AUTOSAR XML (schema 314)
package /ComponentType
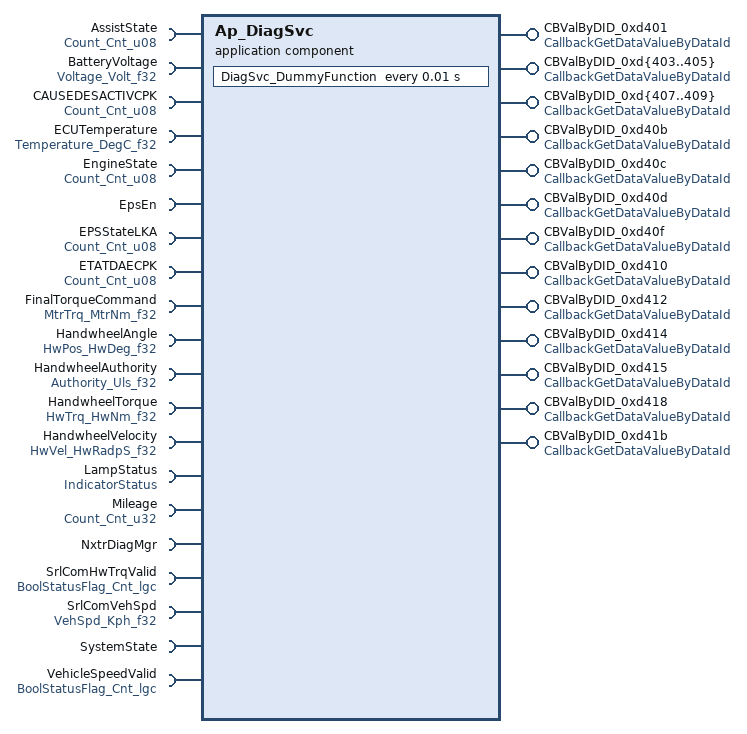
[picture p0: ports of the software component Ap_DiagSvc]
  application software component type Ap_DiagSvc
    17 x provide port, all with server-com-spec{operation=GetDataValueByDataIdentifier, queue-length=1}, provided-interface=CallbackGetDataValueByDataId:
      CBValByDID_0xd401
      CBValByDID_0xd{403..405}
      CBValByDID_0xd{407..409}
      CBValByDID_0xd40b
      CBValByDID_0xd40c
      CBValByDID_0xd40d
      CBValByDID_0xd40f
      CBValByDID_0xd410
      CBValByDID_0xd412
      CBValByDID_0xd414
      CBValByDID_0xd415
      CBValByDID_0xd418
      CBValByDID_0xd41b
    20 x require port:
      AssistState: unqueued-receiver-com-spec{data-element=Cnt_u08, init-value=D_ZERO_CNT_U8}, required-interface=Count_Cnt_u08
      BatteryVoltage: unqueued-receiver-com-spec{data-element=Volt_f32, init-value=D_ZERO_ULS_F32}, required-interface=Voltage_Volt_f32
      CAUSEDESACTIVCPK: unqueued-receiver-com-spec{data-element=Cnt_u08, init-value=D_ZERO_CNT_U8}, required-interface=Count_Cnt_u08
      ECUTemperature: unqueued-receiver-com-spec{data-element=DegC_f32, init-value=D_ZERO_ULS_F32}, required-interface=Temperature_DegC_f32
      EngineState: unqueued-receiver-com-spec{data-element=Cnt_u08, init-value=D_ZERO_CNT_U8}, required-interface=Count_Cnt_u08
      EpsEn: client-com-spec=OP_GET, required-interface=EpsEn
      EPSStateLKA: unqueued-receiver-com-spec{data-element=Cnt_u08, init-value=D_ZERO_CNT_U8}, required-interface=Count_Cnt_u08
      ETATDAECPK: unqueued-receiver-com-spec{data-element=Cnt_u08, init-value=D_ZERO_CNT_U8}, required-interface=Count_Cnt_u08
      FinalTorqueCommand: unqueued-receiver-com-spec{data-element=MtrNm_f32, init-value=D_ZERO_ULS_F32}, required-interface=MtrTrq_MtrNm_f32
      HandwheelAngle: unqueued-receiver-com-spec{data-element=HwDeg_f32, init-value=D_ZERO_ULS_F32}, required-interface=HwPos_HwDeg_f32
      HandwheelAuthority: unqueued-receiver-com-spec{data-element=Uls_f32, init-value=D_ZERO_ULS_F32}, required-interface=Authority_Uls_f32
      HandwheelTorque: unqueued-receiver-com-spec{data-element=HwNm_f32, init-value=D_ZERO_ULS_F32}, required-interface=HwTrq_HwNm_f32
      HandwheelVelocity: unqueued-receiver-com-spec{data-element=HwRadpS_f32, init-value=D_ZERO_ULS_F32}, required-interface=HwVel_HwRadpS_f32
      LampStatus: client-com-spec=GetIndicatorStatus, required-interface=IndicatorStatus
      Mileage: unqueued-receiver-com-spec{data-element=Cnt_u32, init-value=D_ZERO_CNT_U32}, required-interface=Count_Cnt_u32
      NxtrDiagMgr: required-com-specs=[GetNTCActive, GetNTCFailed, GetNTCStatus, SetNTCStatus], required-interface=NxtrDiagMgr
      SrlComHwTrqValid: unqueued-receiver-com-spec{data-element=Cnt_lgc, init-value=D_FALSE_CNT_LGC}, required-interface=BoolStatusFlag_Cnt_lgc
      SrlComVehSpd: unqueued-receiver-com-spec{data-element=Kph_f32, init-value=D_ZERO_ULS_F32}, required-interface=VehSpd_Kph_f32
      SystemState: required-interface=SystemState
      VehicleSpeedValid: unqueued-receiver-com-spec{data-element=Cnt_lgc, init-value=D_FALSE_CNT_LGC}, required-interface=BoolStatusFlag_Cnt_lgc
  internal behavior Ap_DiagSvc_InternalBehavior: component=Ap_DiagSvc
    17 x operation invoked event:
      OIT_CBValByDID_0xd401_GetDataValueByDataIdentifier_CBValByDID_0xd401_GetDataValueByDataIdentifier: start-on-event=CBValByDID_0xd401_GetDataValueByDataIdentifier, operation=CBValByDID_0xd401.GetDataValueByDataIdentifier
      OIT_CBValByDID_0xd{403..405}_GetDataValueByDataIdentifier_CBValByDID_0xd{403..405}_GetDataValueByDataIdentifier: start-on-event=CBValByDID_0xd{403..405}_GetDataValueByDataIdentifier, operation=CBValByDID_0xd{403..405}.GetDataValueByDataIdentifier
      OIT_CBValByDID_0xd{407..409}_GetDataValueByDataIdentifier_CBValByDID_0xd{407..409}_GetDataValueByDataIdentifier: start-on-event=CBValByDID_0xd{407..409}_GetDataValueByDataIdentifier, operation=CBValByDID_0xd{407..409}.GetDataValueByDataIdentifier
      OIT_CBValByDID_0xd40b_GetDataValueByDataIdentifier_CBValByDID_0xd40b_GetDataValueByDataIdentifier: start-on-event=CBValByDID_0xd40b_GetDataValueByDataIdentifier, operation=CBValByDID_0xd40b.GetDataValueByDataIdentifier
      OIT_CBValByDID_0xd40c_GetDataValueByDataIdentifier_CBValByDID_0xd40c_GetDataValueByDataIdentifier: start-on-event=CBValByDID_0xd40c_GetDataValueByDataIdentifier, operation=CBValByDID_0xd40c.GetDataValueByDataIdentifier
      OIT_CBValByDID_0xd40d_GetDataValueByDataIdentifier_CBValByDID_0xd40d_GetDataValueByDataIdentifier: start-on-event=CBValByDID_0xd40d_GetDataValueByDataIdentifier, operation=CBValByDID_0xd40d.GetDataValueByDataIdentifier
      OIT_CBValByDID_0xd40f_GetDataValueByDataIdentifier_CBValByDID_0xd40f_GetDataValueByDataIdentifier: start-on-event=CBValByDID_0xd40f_GetDataValueByDataIdentifier, operation=CBValByDID_0xd40f.GetDataValueByDataIdentifier
      OIT_CBValByDID_0xd410_GetDataValueByDataIdentifier_CBValByDID_0xd410_GetDataValueByDataIdentifier: start-on-event=CBValByDID_0xd410_GetDataValueByDataIdentifier, operation=CBValByDID_0xd410.GetDataValueByDataIdentifier
      OIT_CBValByDID_0xd412_GetDataValueByDataIdentifier_CBValByDID_0xd412_GetDataValueByDataIdentifier: start-on-event=CBValByDID_0xd412_GetDataValueByDataIdentifier, operation=CBValByDID_0xd412.GetDataValueByDataIdentifier
      OIT_CBValByDID_0xd414_GetDataValueByDataIdentifier_CBValByDID_0xd414_GetDataValueByDataIdentifier: start-on-event=CBValByDID_0xd414_GetDataValueByDataIdentifier, operation=CBValByDID_0xd414.GetDataValueByDataIdentifier
      OIT_CBValByDID_0xd415_GetDataValueByDataIdentifier_CBValByDID_0xd415_GetDataValueByDataIdentifier: start-on-event=CBValByDID_0xd415_GetDataValueByDataIdentifier, operation=CBValByDID_0xd415.GetDataValueByDataIdentifier
      OIT_CBValByDID_0xd418_GetDataValueByDataIdentifier_CBValByDID_0xd418_GetDataValueByDataIdentifier: start-on-event=CBValByDID_0xd418_GetDataValueByDataIdentifier, operation=CBValByDID_0xd418.GetDataValueByDataIdentifier
      OIT_CBValByDID_0xd41b_GetDataValueByDataIdentifier_CBValByDID_0xd41b_GetDataValueByDataIdentifier: start-on-event=CBValByDID_0xd41b_GetDataValueByDataIdentifier, operation=CBValByDID_0xd41b.GetDataValueByDataIdentifier
    timing event TMT_DiagSvc_DummyFunction: start-on-event=DiagSvc_DummyFunction, period=0.01
    port-api-options:
      enable-take-address=false, indirect-api=false, port=AssistState
      enable-take-address=false, indirect-api=false, port=BatteryVoltage
      enable-take-address=false, indirect-api=false, port=CAUSEDESACTIVCPK
      enable-take-address=false, indirect-api=false, port=CBValByDID_0xd401
      enable-take-address=false, indirect-api=false, port=CBValByDID_0xd{403..405}
      enable-take-address=false, indirect-api=false, port=CBValByDID_0xd{407..409}
      enable-take-address=false, indirect-api=false, port=CBValByDID_0xd40b
      enable-take-address=false, indirect-api=false, port=CBValByDID_0xd40c
      enable-take-address=false, indirect-api=false, port=CBValByDID_0xd40d
      enable-take-address=false, indirect-api=false, port=CBValByDID_0xd40f
      enable-take-address=false, indirect-api=false, port=CBValByDID_0xd410
      enable-take-address=false, indirect-api=false, port=CBValByDID_0xd412
      enable-take-address=false, indirect-api=false, port=CBValByDID_0xd414
      enable-take-address=false, indirect-api=false, port=CBValByDID_0xd415
      enable-take-address=false, indirect-api=false, port=CBValByDID_0xd418
      enable-take-address=false, indirect-api=false, port=CBValByDID_0xd41b
      enable-take-address=false, indirect-api=false, port=ECUTemperature
      enable-take-address=false, indirect-api=false, port=EngineState
      enable-take-address=false, indirect-api=false, port=EpsEn
      enable-take-address=false, indirect-api=false, port=EPSStateLKA
      enable-take-address=false, indirect-api=false, port=ETATDAECPK
      enable-take-address=false, indirect-api=false, port=FinalTorqueCommand
      enable-take-address=false, indirect-api=false, port=HandwheelAngle
      enable-take-address=false, indirect-api=false, port=HandwheelAuthority
      enable-take-address=false, indirect-api=false, port=HandwheelTorque
      enable-take-address=false, indirect-api=false, port=HandwheelVelocity
      enable-take-address=false, indirect-api=false, port=LampStatus
      enable-take-address=false, indirect-api=false, port=Mileage
      enable-take-address=false, indirect-api=false, port=NxtrDiagMgr
      enable-take-address=false, indirect-api=false, port=SrlComHwTrqValid
      enable-take-address=false, indirect-api=false, port=SrlComVehSpd
      enable-take-address=false, indirect-api=false, port=SystemState
      enable-take-address=false, indirect-api=false, port=VehicleSpeedValid
    18 x runnable:
      CBValByDID_0xd401_GetDataValueByDataIdentifier
        data receive point REC_Mileage_Cnt_u32: data-element=Mileage.Cnt_u32
      CBValByDID_0xd403_GetDataValueByDataIdentifier
        data receive point REC_SrlComVehSpd_Kph_f32: data-element=SrlComVehSpd.Kph_f32
        data receive point REC_VehicleSpeedValid_Cnt_lgc: data-element=VehicleSpeedValid.Cnt_lgc
      CBValByDID_0xd404_GetDataValueByDataIdentifier
        data receive point REC_BatteryVoltage_Volt_f32: data-element=BatteryVoltage.Volt_f32
      CBValByDID_0xd405_GetDataValueByDataIdentifier
        data receive point REC_ECUTemperature_DegC_f32: data-element=ECUTemperature.DegC_f32
        sync call SC_NxtrDiagMgr_GetNTCFailed: operation=NxtrDiagMgr.GetNTCFailed, timeout=0
      CBValByDID_0xd407_GetDataValueByDataIdentifier
        data receive point REC_EngineState_Cnt_u08: data-element=EngineState.Cnt_u08
        sync call SC_NxtrDiagMgr_GetNTCFailed: operation=NxtrDiagMgr.GetNTCFailed, timeout=0
      CBValByDID_0xd408_GetDataValueByDataIdentifier
        sync call SC_EpsEn_OP_GET: operation=EpsEn.OP_GET, timeout=0
      CBValByDID_0xd409_GetDataValueByDataIdentifier
        data receive point REC_AssistState_Cnt_u08: data-element=AssistState.Cnt_u08
      CBValByDID_0xd40b_GetDataValueByDataIdentifier
        sync call SC_NxtrDiagMgr_GetNTCActive: operation=NxtrDiagMgr.GetNTCActive, timeout=0
      CBValByDID_0xd40c_GetDataValueByDataIdentifier
      CBValByDID_0xd40d_GetDataValueByDataIdentifier
        data receive point REC_HandwheelAngle_HwDeg_f32: data-element=HandwheelAngle.HwDeg_f32
        data receive point REC_HandwheelAuthority_Uls_f32: data-element=HandwheelAuthority.Uls_f32
      CBValByDID_0xd40f_GetDataValueByDataIdentifier
        data receive point REC_HandwheelTorque_HwNm_f32: data-element=HandwheelTorque.HwNm_f32
        data receive point REC_SrlComHwTrqValid_Cnt_lgc: data-element=SrlComHwTrqValid.Cnt_lgc
      CBValByDID_0xd410_GetDataValueByDataIdentifier
        data receive point REC_FinalTorqueCommand_MtrNm_f32: data-element=FinalTorqueCommand.MtrNm_f32
      CBValByDID_0xd412_GetDataValueByDataIdentifier
        sync call SC_NxtrDiagMgr_GetNTCFailed: operation=NxtrDiagMgr.GetNTCFailed, timeout=0
      CBValByDID_0xd414_GetDataValueByDataIdentifier
        data receive point REC_CAUSEDESACTIVCPK_Cnt_u08: data-element=CAUSEDESACTIVCPK.Cnt_u08
      CBValByDID_0xd415_GetDataValueByDataIdentifier
        data receive point REC_ETATDAECPK_Cnt_u08: data-element=ETATDAECPK.Cnt_u08
      CBValByDID_0xd418_GetDataValueByDataIdentifier
        data receive point REC_HandwheelVelocity_HwRadpS_f32: data-element=HandwheelVelocity.HwRadpS_f32
      CBValByDID_0xd41b_GetDataValueByDataIdentifier
      DiagSvc_DummyFunction
  swc implementation Ap_DiagSvc_Implementation: behavior=Ap_DiagSvc_InternalBehavior
    code-descriptors:
      code Code: type=SRC
